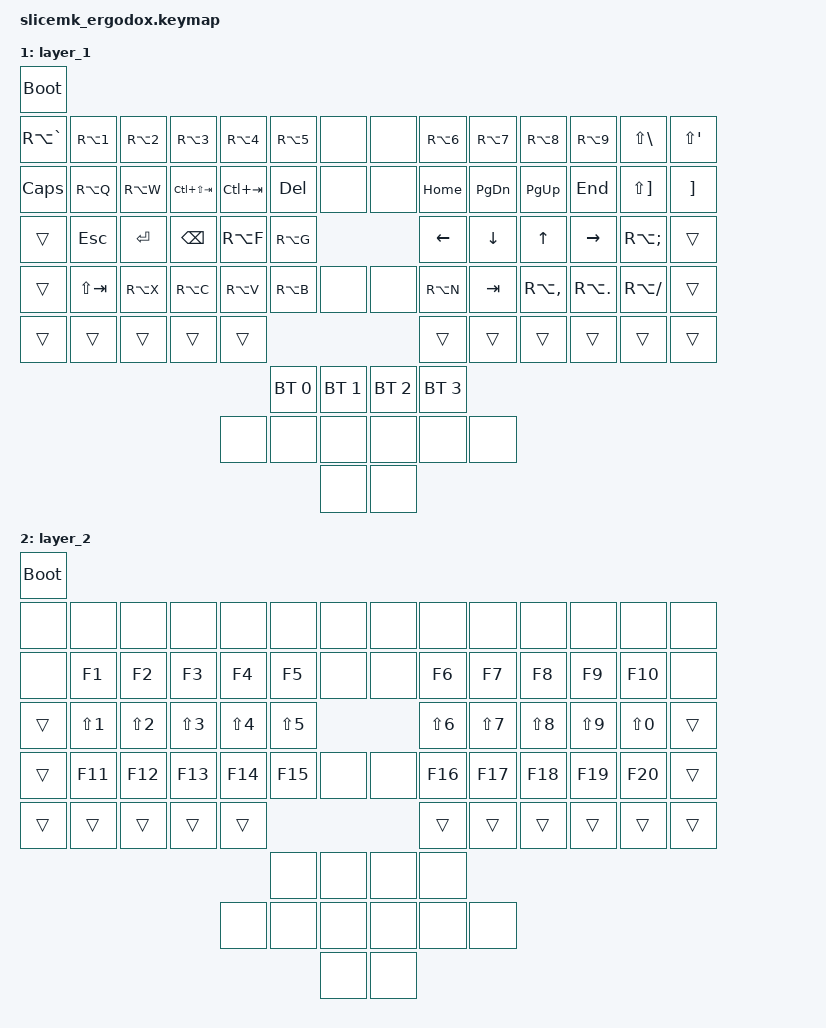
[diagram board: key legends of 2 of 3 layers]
#include <behaviors.dtsi>
#include <dt-bindings/zmk/bt.h>
#include <dt-bindings/zmk/keys.h>
#include <dt-bindings/zmk/outputs.h>

/ {
    combos {
        compatible = "zmk,combos";
        combo_esc {
            timeout-ms = <50>;
            key-positions = <1 2>;
            bindings = <&kp LS(APOS)>;
        };
    };
	macros {
		carret: carret {
			label = "carret";
			compatible = "zmk,behavior-macro";
			#binding-cells = <0>;
			bindings
				// = <&macro_press &kp LSHFT>
				= <&macro_tap &kp RA(NUMBER_3) &kp SPC>
				// , <&macro_release &kp LSHFT>
				;
		};
		backtick: backtick {
			label = "backtick";
			compatible = "zmk,behavior-macro";
			#binding-cells = <0>;
			bindings
				// = <&macro_press &kp LSHFT>
				= <&macro_tap &kp RA(NUMBER_7) &kp SPC>
				// , <&macro_release &kp LSHFT>
				;
		};
	};
	keymap {
		compatible = "zmk,keymap";

		// This is the default test layer meant for testing that every key on
		// your keyboard works. Once you have completed this basic test, you can
		// delete this first section and layer_0 will become your default layer.

		layer_0 {
			bindings = <
				&bootloader
				&kp GRAV    &kp NUMBER_1 &kp NUMBER_2 &kp NUMBER_3 &kp NUMBER_4 &kp NUMBER_5 &kp RA(B)    &kp RA(N)     &kp NUMBER_6  &kp NUMBER_7 &kp NUMBER_8 &kp NUMBER_9 &kp NUMBER_0  &kp MINUS
				&kp TAB     &kp Q        &kp W        &kp E        &kp R        &kp T        &kp LS(RBKT) &kp RBKT      &kp Y         &kp U        &kp I        &kp O        &kp P         &kp LBKT
				&kp LCTRL   &kp A        &kp S        &kp D        &kp F        &kp G                                   &kp H         &kp J        &kp K        &kp L        &kp SEMICOLON &kp LCTRL
				&kp LSHIFT  &kp Z        &kp X        &kp C        &kp V        &kp B        &kp RA(F)    &kp RA(G)     &kp N         &kp M        &kp CMMA     &kp DOT      &kp FSLH      &kp RSHIFT
				&kp LCTRL   &none        &none        &kp LWIN     &kp LALT                                                           &mo 1        &mo 2        &kp RALT     &kp RCTRL     &kp LCTRL
				                                                                &kp ESC      &kp PGUP     &kp BACKSPACE &kp DEL 
				                                                   &mo 1        &mo 2        &kp PGDN     &kp ENTER     &kp BACKSPACE &kp SPC
				                                                                             &kp LCTRL    &kp RCTRL
			>;
		};
		layer_1 {
			bindings = <
				&bootloader
				&kp RA(GRAV)       &kp RA(NUMBER_1)    &kp RA(NUMBER_2)   &kp RA(NUMBER_3) &kp RA(NUMBER_4)  &kp RA(NUMBER_5) &none          &none           &kp RA(NUMBER_6)  &kp RA(NUMBER_7)  &kp RA(NUMBER_8)  &kp RA(NUMBER_9)  &kp LS(BSLH)      &kp LS(APOS)
				&kp CAPSLOCK       &kp RA(Q)           &kp RA(W)          &kp LC(LS(TAB))  &kp LC(TAB)       &kp DEL          &none          &none           &kp HOME          &kp PG_DN         &kp PG_UP         &kp END           &kp LS(RBKT)      &kp RBKT  
				&trans             &kp ESC             &kp ENTER          &kp BACKSPACE    &kp RA(F)         &kp RA(G)                                       &kp LEFT          &kp DOWN          &kp UP            &kp RIGHT         &kp RA(SEMICOLON) &trans
				&trans             &kp LS(TAB)         &kp RA(X)          &kp RA(C)        &kp RA(V)         &kp RA(B)        &none          &none           &kp RA(N)         &kp TAB           &kp RA(CMMA)      &kp RA(DOT)       &kp RA(FSLH)      &trans
				&trans             &trans              &trans             &trans           &trans                                                            &trans            &trans            &trans            &trans            &trans            &trans
				                                                                                             &bt BT_SEL 0     &bt BT_SEL 1   &bt BT_SEL 2    &bt BT_SEL 3     
				                                                                           &none             &none            &none          &none           &none             &none
				                                                                                                              &none          &none           
			>;
		};
		layer_2 {
			bindings = <
				&bootloader
				&none            &none            &none            &none            &none             &none            &none     &none     &none            &none            &none            &none             &none             &none
				&none            &kp F1           &kp F2           &kp F3           &kp F4            &kp F5           &none     &none     &kp F6           &kp F7           &kp F8           &kp F9            &kp F10           &none
				&trans           &kp LS(NUMBER_1) &kp LS(NUMBER_2) &kp LS(NUMBER_3) &kp LS(NUMBER_4)  &kp LS(NUMBER_5)                     &kp LS(NUMBER_6) &kp LS(NUMBER_7) &kp LS(NUMBER_8) &kp LS(NUMBER_9)  &kp LS(NUMBER_0)  &trans 
				&trans           &kp F11          &kp F12          &kp F13          &kp F14           &kp F15          &none     &none     &kp F16          &kp F17          &kp F18          &kp F19           &kp F20           &trans
				&trans           &trans           &trans           &trans           &trans                                                 &trans           &trans           &trans           &trans            &trans            &trans 
				                                                                                      &none            &none     &none     &none    
				                                                                    &none             &none            &none     &none     &none            &none
				                                                                                                       &none     &none     
			>;
		};
	};
};
